# MCXN947_cm33_core0 register map
Vendor: nxp.com; File version: 1.0
CPU: CM33 r2p0, little endian, MPU, FPU, VTOR, 3 interrupt priority bits
Registers are 32-bit, read-write, reset 0x0 unless marked. A register's access mark holds for its fields unless they carry their own. Offsets are from the block's base; [hi:lo] are bit positions; lines under a group give offsets from that group; {n}, {i} and the like mark numbered series; 'fields as' and 'values as' point back to an identical list.

## MRT0 — Multi-Rate Timer (MRT)
Base 0x40013000
{0x0+0x10*i} CHANNEL[{i}] (i=0..3) group
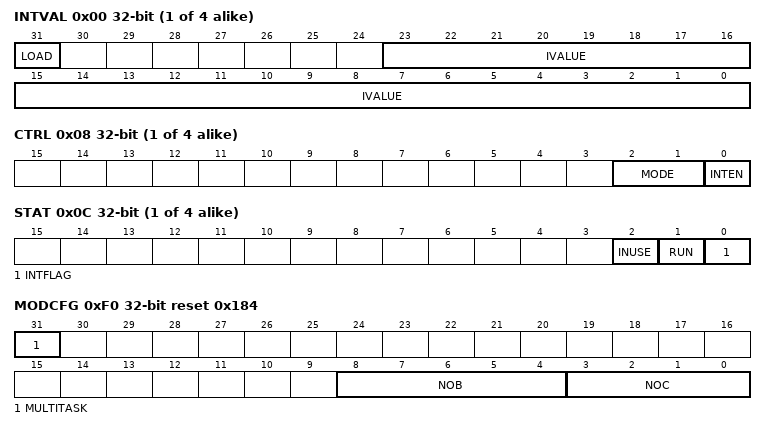
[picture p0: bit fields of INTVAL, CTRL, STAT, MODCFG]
  0x00 INTVAL — Time Interval Value
    [31] LOAD — Force Load Enable
      0=NO_FORCE_LOAD; 1=FORCE_LOAD
    [23:0] IVALUE — Time Interval Load Value.
  0x04 TIMER ro reset 0xFFFFFF
    [23:0] VALUE — Current Timer Value
  0x08 CTRL — Control
    [2:1] MODE — MRT Operating mode
      0=REPEAT_INTERRUPT_MODE; 1=ONE_SHOT_INTERRUPT_MODE; 2=ONE_SHOT_STALL_MODE
    [0] INTEN — Interrupt request
      0=DISABLED; 1=ENABLED
  0x0C STAT — Status
    [2] INUSE write-1-clears — Channel-In-Use flag
      0=NO (This timer channel is not in use.); 1=YES (This timer channel is in use.)
    [1] RUN ro — Timer n State
      0=IDLE_STATE; 1=RUNNING
    [0] INTFLAG — Monitors the interrupt flag. Writing 0 indicates no pending interrupt or no operation. Writing 1 indicates pending interrupt, because TIMERn has reached the end of the time interval. If CTRL and the global interrupt are generated. Writing 1 to this field bit clears the interrupt request.n in the CONTROLn also gets 1, then the interrupt for timer channel n
      0=NO_PENDING_INTERRUPT; 1=PENDING_INTERRUPT
0xF0 MODCFG reset 0x184 — Module Configuration
  [31] MULTITASK
    0=HARDWARE_STATUS_MODE; 1=MULTI_TASK_MODE
  [8:4] NOB — Number of Bits
  [3:0] NOC — Number of Channels
0xF4 IDLE_CH ro — Idle Channel
  [7:4] CHAN
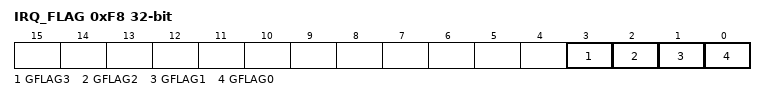
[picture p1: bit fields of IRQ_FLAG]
0xF8 IRQ_FLAG — Global Interrupt Flag
  [3] GFLAG3 — Interrupt Flag
  [2] GFLAG2 — Interrupt Flag
  [1] GFLAG1 — Interrupt Flag
  [0] GFLAG0 — Interrupt Flag
    0=NO_PENDING_INTERRUPT; 1=PENDING_INTERRUPT

## WWDT0 — WWDT
Base 0x40016000
Same registers: WWDT1 0x40017000
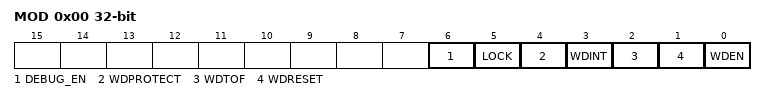
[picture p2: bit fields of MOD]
0x00 MOD — Mode
  [6] DEBUG_EN — Debug Enable
    0=DISABLE (Disabled); 1=ENABLE (Enabled)
  [5] LOCK
    0=NO_LOCK; 1=LOCK
  [4] WDPROTECT — Watchdog Update Mode
    0=FLEXIBLE; 1=THRESHOLD
  [3] WDINT write-1-clears — Warning Interrupt Flag
    0=NO_FLAG; 1=FLAG
  [2] WDTOF — Watchdog Timeout Flag
    0=CLEAR (Watchdog event has not occurred.); 1=RESET (Watchdog event has occurred (causes a chip reset if WDRESET = 1).)
  [1] WDRESET — Watchdog Reset Enable
    0=INTERRUPT; 1=RESET
  [0] WDEN — Watchdog Enable
    0=STOP (Timer stopped); 1=RUN (Timer running)
0x04 TC reset 0xFF — Timer Constant
  [23:0] COUNT — Watchdog Timeout Value
0x08 FEED wo reset not defined — Feed Sequence
  [7:0] FEED — Feed Value
0x0C TV ro reset 0xFF — Timer Value
  [23:0] COUNT — Counter Timer Value
0x14 WARNINT — Warning Interrupt Compare Value
  [9:0] WARNINT — Watchdog Warning Interrupt Compare Value
0x18 WINDOW reset 0xFFFFFF — Window Compare Value
  [23:0] WINDOW — Watchdog Window Value

## CACHE64_CTRL0 — CACHE64_CTRL
Base 0x4001B000
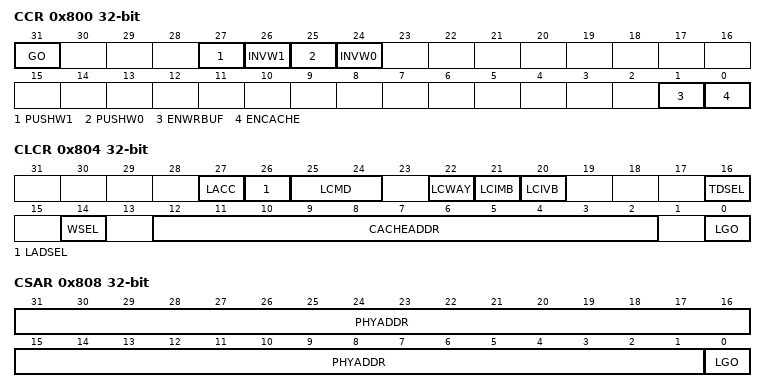
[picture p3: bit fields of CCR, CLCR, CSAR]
0x800 CCR — Cache Control
  [31] GO — Initiate Cache Command
    0=no_effect (Write: no effect; Read: no cache command active); 1=init_cmd (Write: initiates cache command; Read: cache command active)
  [27] PUSHW1 — Push Way 1
    0=no_operation; 1=pushw1 (Push all modified lines in way 1)
  [26] INVW1 — Invalidate Way 1
    0=no_operation; 1=invw1 (Invalidates all lines in way 1)
  [25] PUSHW0 — Push Way 0
    0=no_operation; 1=pushw0 (Push all modified lines in way 0)
  [24] INVW0 — Invalidate Way 0
    0=no_operation; 1=invw0 (Invalidates all lines in way 0)
  [1] ENWRBUF — Enable Write Buffer
    0=disabled (Disables); 1=enabled (Enables)
  [0] ENCACHE — Cache Enable
    0=disabled (Disables); 1=enabled (Enables)
0x804 CLCR — Cache Line Control
  [27] LACC — Line Access Type
    0=read; 1=write
  [26] LADSEL — Line Address Select
    0=cache_addr; 1=phys_addr (Physical)
  [25:24] LCMD — Line Command
    0=search_rw (Search and read or write); 1=invalidate; 2=push; 3=clear
  [22] LCWAY — Line Command Way
    0=way0; 1=way1
  [21] LCIMB — Line Command Initial Modified Bit
    0=Initial state 0; 1=Initial state 1
  [20] LCIVB — Line Command Initial Valid Bit
    0=Initial state 0; 1=Initial state 1
  [16] TDSEL — Tag Or Data Select
    0=data; 1=tag
  [14] WSEL — Way Select
    0=way0; 1=way1
  [12:2] CACHEADDR — Cache Address
  [0] LGO — Initiate Cache Line Command
    0=no_effect (Write: no effect; Read: no line command active); 1=init_cmd (Write: initiate line command; Read: line command active)
0x808 CSAR — Cache Search Address
  [31:1] PHYADDR — Physical Address
  [0] LGO — Initiate Cache Line Command
    values as CLCR.LGO
0x80C CCVR — Cache Read/Write Value
  [31:0] DATA — Cache Read/Write Data
